# MKV44F15 register map
Vendor: Freescale Semiconductor, Inc.; Series: Kinetis_V; File version: 1.6
CPU: CM4 r0p1, little endian, no MPU, FPU, VTOR, 4 interrupt priority bits
Registers are 32-bit, read-write, reset 0x0 unless marked. A register's access mark holds for its fields unless they carry their own. Offsets are from the block's base; [hi:lo] are bit positions; {n}, {i} and the like mark numbered series; 'fields as' and 'values as' point back to an identical list.

## XBARB — Crossbar Switch
Base 0x4005A000; register names take the prefix XBARB_
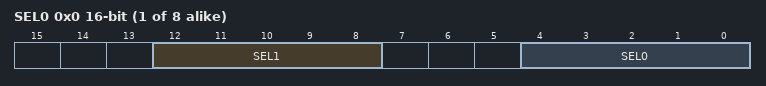
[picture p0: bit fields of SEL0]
{0x0+2i} SEL{i} 16-bit (i=0..7) — Crossbar B Select Register {i}
  [12:8] SEL{2i+1}, [4:0] SEL{2i}

## AOI — AND/OR/INVERT module
Base 0x4005B000; register names take the prefix AOI_
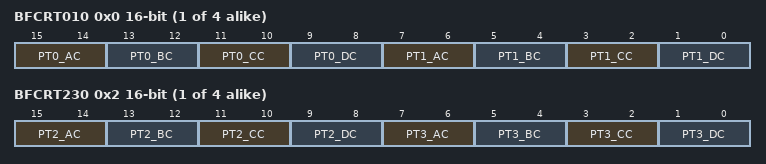
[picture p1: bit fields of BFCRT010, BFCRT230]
{0x0+4i} BFCRT01{i} (i=0..3) 16-bit — Boolean Function Term 0 and 1 Configuration Register for EVENTn
  [15:14] PT0_AC — Product term 0, A input configuration
    0=Force the A input in this product term to a logical zero; 1=Pass the A input in this product term; 2=Complement the A input in this product term; 3=Force the A input in this product term to a logical one
  [13:12] PT0_BC — Product term 0, B input configuration
    0=Force the B input in this product term to a logical zero; 1=Pass the B input in this product term; 2=Complement the B input in this product term; 3=Force the B input in this product term to a logical one
  [11:10] PT0_CC — Product term 0, C input configuration
    0=Force the C input in this product term to a logical zero; 1=Pass the C input in this product term; 2=Complement the C input in this product term; 3=Force the C input in this product term to a logical one
  [9:8] PT0_DC — Product term 0, D input configuration
    0=Force the D input in this product term to a logical zero; 1=Pass the D input in this product term; 2=Complement the D input in this product term; 3=Force the D input in this product term to a logical one
  [7:6] PT1_AC — Product term 1, A input configuration
    values as PT0_AC
  [5:4] PT1_BC — Product term 1, B input configuration
    values as PT0_BC
  [3:2] PT1_CC — Product term 1, C input configuration
    values as PT0_CC
  [1:0] PT1_DC — Product term 1, D input configuration
    values as PT0_DC
{0x2+4i} BFCRT23{i} (i=0..3) 16-bit — Boolean Function Term 2 and 3 Configuration Register for EVENTn
  [15:14] PT2_AC — Product term 2, A input configuration
    values as BFCRT010.PT0_AC
  [13:12] PT2_BC — Product term 2, B input configuration
    values as BFCRT010.PT0_BC
  [11:10] PT2_CC — Product term 2, C input configuration
    values as BFCRT010.PT0_CC
  [9:8] PT2_DC — Product term 2, D input configuration
    values as BFCRT010.PT0_DC
  [7:6] PT3_AC — Product term 3, A input configuration
    values as BFCRT010.PT0_AC
  [5:4] PT3_BC — Product term 3, B input configuration
    values as BFCRT010.PT0_BC
  [3:2] PT3_CC — Product term 3, C input configuration
    values as BFCRT010.PT0_CC
  [1:0] PT3_DC — Product term 3, D input configuration
    values as BFCRT010.PT0_DC

## EWM — External Watchdog Monitor
Base 0x40061000; register names take the prefix EWM_
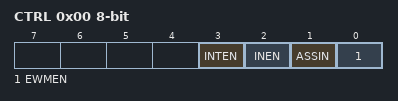
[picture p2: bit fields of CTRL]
0x00 CTRL 8-bit — Control Register
  [3] INTEN — Interrupt Enable.
  [2] INEN — Input Enable.
  [1] ASSIN — EWM_in's Assertion State Select.
  [0] EWMEN — EWM enable.
0x01 SERV 8-bit wo — Service Register
  [7:0] SERVICE
0x02 CMPL 8-bit — Compare Low Register
  [7:0] COMPAREL
0x03 CMPH 8-bit reset 0xFF — Compare High Register
  [7:0] COMPAREH

## OSC — Oscillator
Base 0x40065000; register names take the prefix OSC_
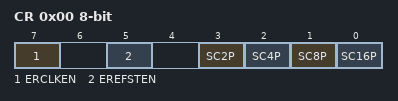
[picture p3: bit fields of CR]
0x00 CR 8-bit — OSC Control Register
  [7] ERCLKEN — External Reference Enable
    0=External reference clock is inactive; 1=External reference clock is enabled
  [5] EREFSTEN — External Reference Stop Enable
    0=External reference clock is disabled in Stop mode; 1=External reference clock stays enabled in Stop mode if ERCLKEN is set before entering Stop mode
  [3] SC2P — Oscillator 2 pF Capacitor Load Configure
    0=Disable the selection; 1=Add 2 pF capacitor to the oscillator load
  [2] SC4P — Oscillator 4 pF Capacitor Load Configure
    0=Disable the selection; 1=Add 4 pF capacitor to the oscillator load
  [1] SC8P — Oscillator 8 pF Capacitor Load Configure
    0=Disable the selection; 1=Add 8 pF capacitor to the oscillator load
  [0] SC16P — Oscillator 16 pF Capacitor Load Configure
    0=Disable the selection; 1=Add 16 pF capacitor to the oscillator load
0x02 DIV 8-bit — OSC_DIV
  [7:6] ERPS
    0=The divisor ratio is 1; 1=The divisor ratio is 2; 2=The divisor ratio is 4; 3=The divisor ratio is 8
